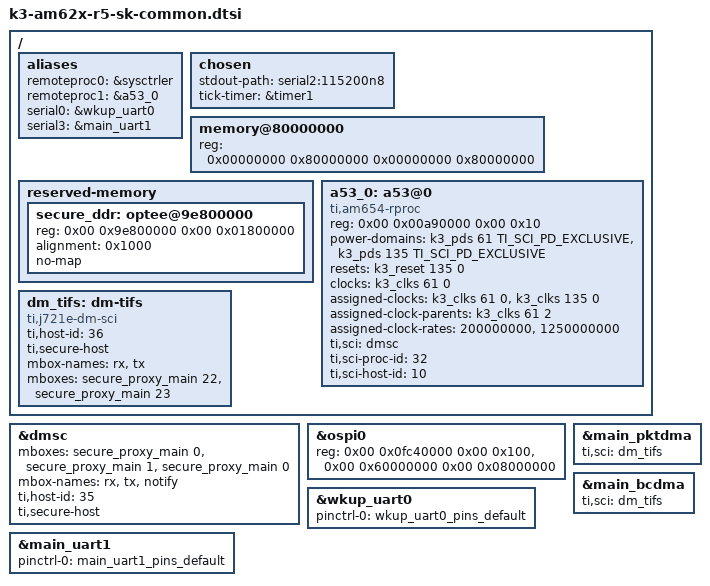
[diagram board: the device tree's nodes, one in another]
// SPDX-License-Identifier: GPL-2.0
/*
 * Common dtsi file for R5 SPL for AM62x SK and derivatives
 * Copyright (C) 2021-2022 Texas Instruments Incorporated - https://www.ti.com/
 */

/ {
	aliases {
		remoteproc0 = &sysctrler;
		remoteproc1 = &a53_0;
		serial0 = &wkup_uart0;
		serial3 = &main_uart1;
	};

	chosen {
		stdout-path = "serial2:115200n8";
		tick-timer = &timer1;
	};

	memory@80000000 {
		device_type = "memory";
		/* 2G RAM */
		reg = <0x00000000 0x80000000 0x00000000 0x80000000>;
		bootph-pre-ram;
	};

	reserved-memory {
		#address-cells = <2>;
		#size-cells = <2>;
		ranges;

		secure_ddr: optee@9e800000 {
			reg = <0x00 0x9e800000 0x00 0x01800000>; /* for OP-TEE */
			alignment = <0x1000>;
			no-map;
		};
	};

	a53_0: a53@0 {
		compatible = "ti,am654-rproc";
		reg = <0x00 0x00a90000 0x00 0x10>;
		power-domains = <&k3_pds 61 TI_SCI_PD_EXCLUSIVE>,
				<&k3_pds 135 TI_SCI_PD_EXCLUSIVE>;
		resets = <&k3_reset 135 0>;
		clocks = <&k3_clks 61 0>;
		assigned-clocks = <&k3_clks 61 0>, <&k3_clks 135 0>;
		assigned-clock-parents = <&k3_clks 61 2>;
		assigned-clock-rates = <200000000>, <1250000000>;
		ti,sci = <&dmsc>;
		ti,sci-proc-id = <32>;
		ti,sci-host-id = <10>;
		bootph-pre-ram;
	};

	dm_tifs: dm-tifs {
		compatible = "ti,j721e-dm-sci";
		ti,host-id = <36>;
		ti,secure-host;
		mbox-names = "rx", "tx";
		mboxes= <&secure_proxy_main 22>,
			<&secure_proxy_main 23>;
		bootph-pre-ram;
	};
};

&dmsc {
	mboxes= <&secure_proxy_main 0>,
		<&secure_proxy_main 1>,
		<&secure_proxy_main 0>;
	mbox-names = "rx", "tx", "notify";
	ti,host-id = <35>;
	ti,secure-host;
};

&ospi0 {
	reg = <0x00 0x0fc40000 0x00 0x100>,
	      <0x00 0x60000000 0x00 0x08000000>;
};

&main_pktdma {
	ti,sci = <&dm_tifs>;
};

&main_bcdma {
	ti,sci = <&dm_tifs>;
};

/* WKUP UART0 is used for DM firmware logs */
&wkup_uart0 {
	pinctrl-names = "default";
	pinctrl-0 = <&wkup_uart0_pins_default>;
	status = "okay";
	bootph-pre-ram;
};

/* Main UART1 is used for TIFS firmware logs */
&main_uart1 {
	pinctrl-names = "default";
	pinctrl-0 = <&main_uart1_pins_default>;
	status = "okay";
	bootph-pre-ram;
};
